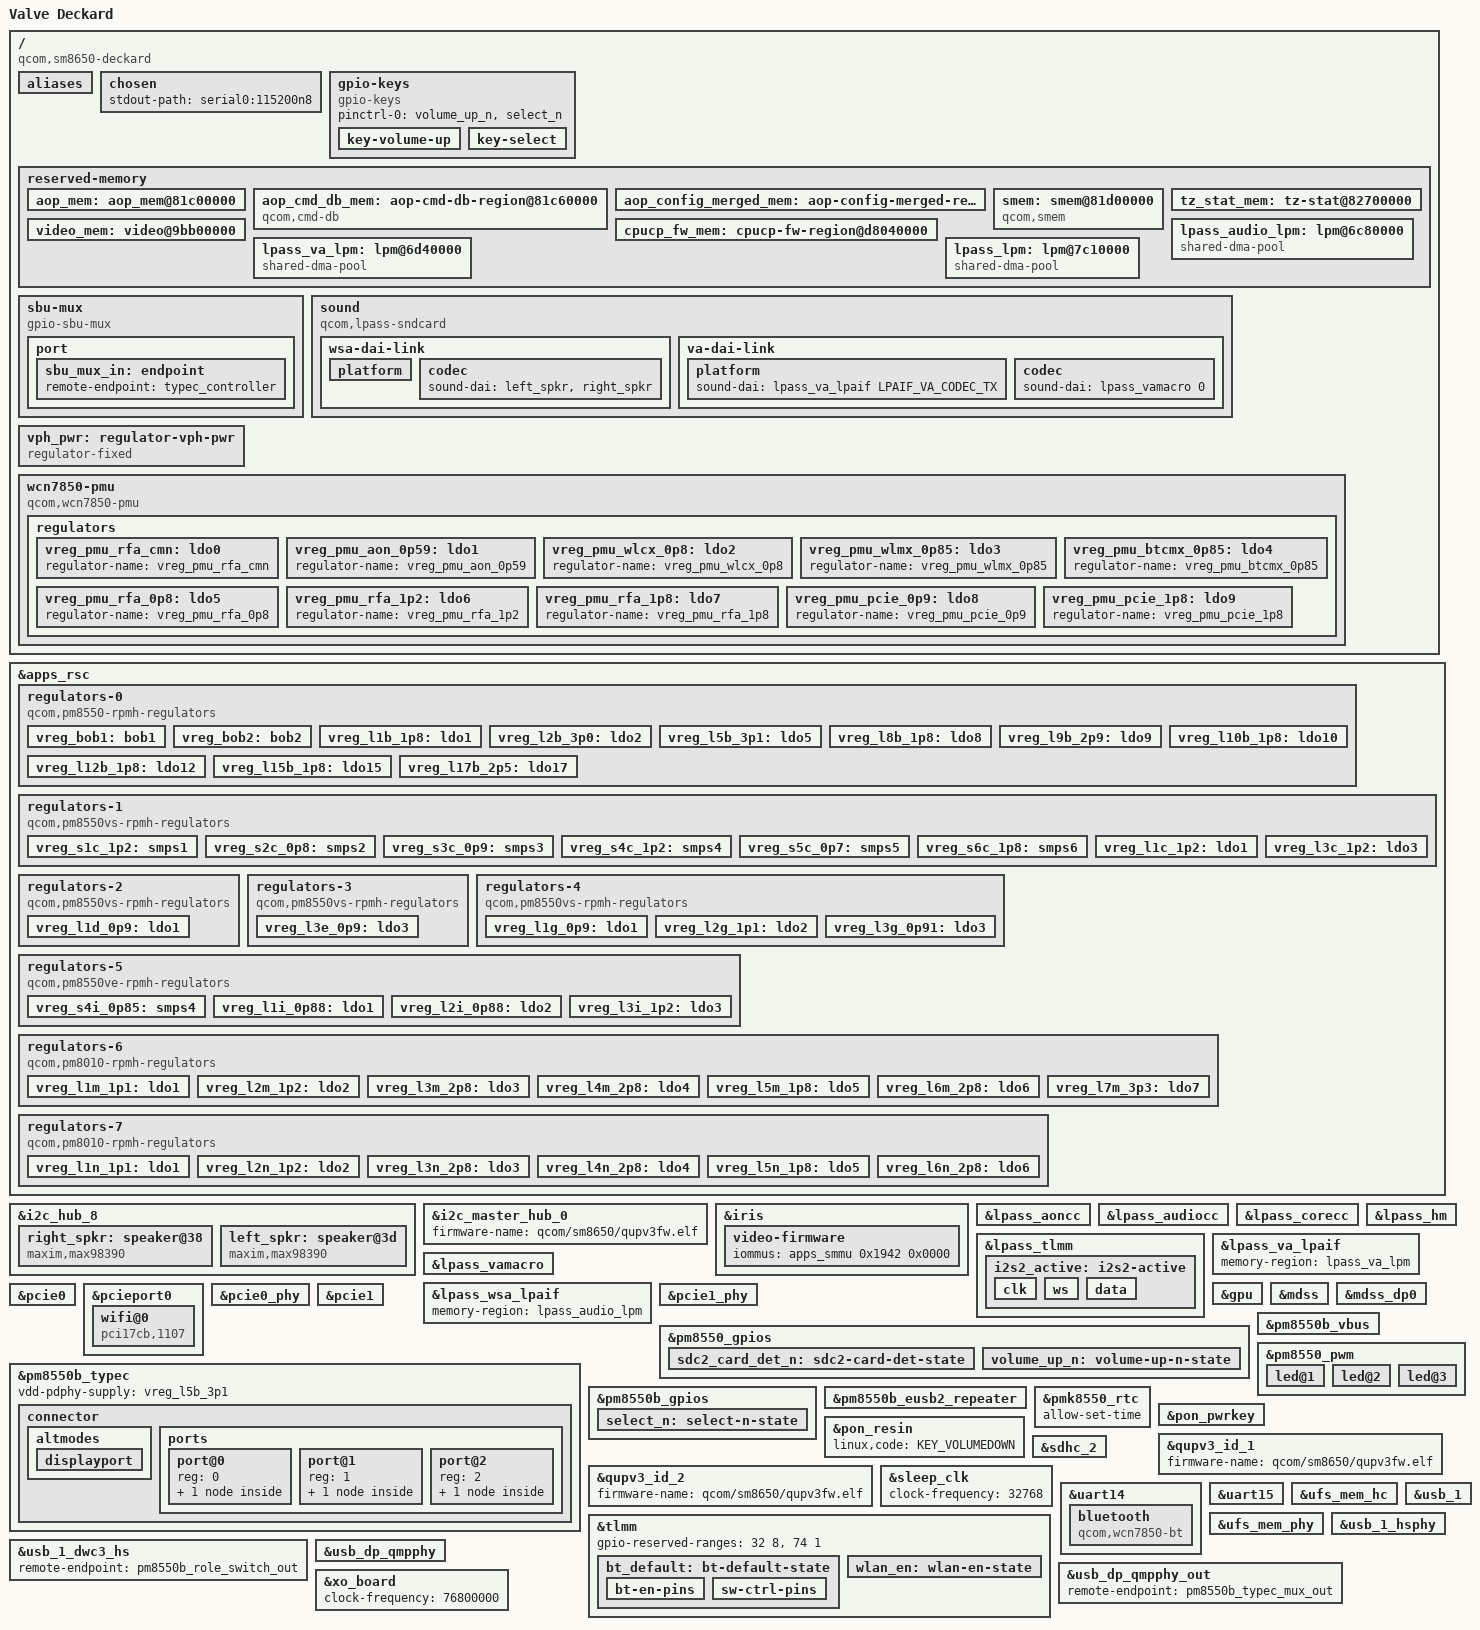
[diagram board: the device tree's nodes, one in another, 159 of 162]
// SPDX-License-Identifier: BSD-3-Clause
/*
 * Copyright (c) 2025
 */

/dts-v1/;

#include <dt-bindings/leds/common.h>
#include <dt-bindings/regulator/qcom,rpmh-regulator.h>
#include <dt-bindings/sound/qcom,lpaif-v5.h>
#include <dt-bindings/usb/pd.h>
#include "sm8650.dtsi"
#include "pm8010.dtsi"
#include "pm8550.dtsi"
#include "pm8550b.dtsi"
#define PMK8550VE_SID 8
#include "pm8550ve.dtsi"
#include "pm8550vs.dtsi"
#include "pmk8550.dtsi"

/* most of the sm8650.dtsi reserved-memory isn't applicable, redefine it from scratch
 * also delete anything that depends on the deleted regions to compile the dts
 */
/delete-node/ &reserved_memory;
/delete-node/ &remoteproc_mpss;
/delete-node/ &remoteproc_adsp;
/delete-node/ &remoteproc_cdsp;
/delete-node/ &ipa;
/delete-node/ &lpass_txmacro;
/delete-node/ &lpass_rxmacro;
/delete-node/ &lpass_wsamacro;
/delete-node/ &lpass_wsa2macro;
/delete-node/ &swr0;
/delete-node/ &swr1;
/delete-node/ &swr2;
/delete-node/ &swr3;

/ {
	model = "Valve Deckard";
	compatible = "qcom,sm8650-deckard", "qcom,sm8650";
	chassis-type = "embedded";

	/delete-node/ smp2p-adsp;
	/delete-node/ smp2p-cdsp;
	/delete-node/ smp2p-modem;

	aliases {
		serial0 = &uart15;
		serial1 = &uart14;
	};

	chosen {
		stdout-path = "serial0:115200n8";
	};

	gpio-keys {
		compatible = "gpio-keys";

		pinctrl-0 = <&volume_up_n>, <&select_n>;
		pinctrl-names = "default";

		key-volume-up {
			label = "Volume Up";
			linux,code = <KEY_VOLUMEUP>;
			gpios = <&pm8550_gpios 6 GPIO_ACTIVE_LOW>;
			debounce-interval = <15>;
			linux,can-disable;
		};

		key-select {
			label = "Select";
			linux,code = <KEY_SELECT>;
			gpios = <&pm8550b_gpios 5 GPIO_ACTIVE_LOW>;
			debounce-interval = <15>;
			linux,can-disable;
		};
	};

	reserved-memory {
		#address-cells = <2>;
		#size-cells = <2>;
		ranges;

		aop_mem: aop_mem@81c00000 {
			no-map;
			reg = <0x0 0x81c00000 0x0 0x60000>;
		};

		aop_cmd_db_mem: aop-cmd-db-region@81c60000 {
			compatible = "qcom,cmd-db";
			reg = <0x0 0x81c60000 0x0 0x20000>;
			no-map;
		};

		/* merged aop_config, tme_crash_dump, tme_log */
		aop_config_merged_mem: aop-config-merged-region@81c80000 {
			reg = <0x0 0x81c80000 0x0 0x75000>; // without TZ: size 0x64000
			no-map;
		};

		smem: smem@81d00000 {
			compatible = "qcom,smem";
			reg = <0x0 0x81d00000 0x0 0x200000>;
			hwlocks = <&tcsr_mutex 3>;
			no-map;
		};

		// with TZ only:
		tz_stat_mem: tz-stat@82700000 {
			reg = <0 0x82700000 0 0x100000>;
			no-map;
		};

		cpucp_fw_mem: cpucp-fw-region@d8040000 {
			reg = <0x0 0xd8040000 0x0 0x1b2000>;
			no-map;
		};

		/* note: can be any free 8MB region (driver needs a fixed region) */
		video_mem: video@9bb00000 {
			reg = <0 0x9bb00000 0 0x800000>;
			no-map;
		};

		/* not regular memory: */

		lpass_audio_lpm: lpm@6c80000 {
			compatible = "shared-dma-pool";
			reg = <0 0x06c80000 0 0x10000>;
			no-map;
		};

		lpass_va_lpm: lpm@6d40000 {
			compatible = "shared-dma-pool";
			reg = <0 0x06d40000 0 0x3000>;
			no-map;
		};

		lpass_lpm: lpm@7c10000 {
			compatible = "shared-dma-pool";
			reg = <0 0x07c10000 0 0x8000>;
			no-map;
		};
	};

	sbu-mux {
		compatible = "gpio-sbu-mux";

		enable-gpios = <&tlmm 86 GPIO_ACTIVE_LOW>;
		select-gpios = <&tlmm 82 GPIO_ACTIVE_HIGH>;

		mode-switch;
		orientation-switch;

		port {
			sbu_mux_in: endpoint {
				remote-endpoint = <&typec_controller>;
			};
		};

		// XXX: needs VREG_L05B_3P1, VREG_BOB2
	};

	sound {
		compatible = "qcom,lpass-sndcard";
		model = "SM8650-DECKARD";

		pinctrl-0 = <&i2s2_active>;
		pinctrl-names = "default";

		wsa-dai-link {
			link-name = "SPKR Playback";

			clocks = <&lpass_audiocc LPASS_AUDIO_CC_EXT_IF2_IBIT_CLK>;

			platform {
				sound-dai = <&lpass_wsa_lpaif LPAIF_WSA_LPASS_I2S2>;
			};

			codec {
				sound-dai = <&left_spkr>, <&right_spkr>;
			};
		};

		va-dai-link {
			link-name = "VA Capture";
			capture;

			platform {
				sound-dai = <&lpass_va_lpaif LPAIF_VA_CODEC_TX>;
			};

			codec {
				sound-dai = <&lpass_vamacro 0>;
			};
		};
	};

	vph_pwr: regulator-vph-pwr {
		compatible = "regulator-fixed";

		regulator-name = "vph_pwr";
		regulator-min-microvolt = <3700000>;
		regulator-max-microvolt = <3700000>;

		regulator-always-on;
		regulator-boot-on;
	};

	wcn7850-pmu {
		compatible = "qcom,wcn7850-pmu";

		pinctrl-names = "default";
		pinctrl-0 = <&wlan_en>, <&bt_default>;

		wlan-enable-gpios = <&tlmm 16 GPIO_ACTIVE_HIGH>;
		bt-enable-gpios = <&tlmm 17 GPIO_ACTIVE_HIGH>;

		vdd-supply = <&vreg_s4i_0p85>;
		vddio-supply = <&vreg_l15b_1p8>;
		vddio1p2-supply = <&vreg_l3c_1p2>;
		vddaon-supply = <&vreg_s2c_0p8>;
		vdddig-supply = <&vreg_s3c_0p9>;
		vddrfa1p2-supply = <&vreg_s1c_1p2>;
		vddrfa1p8-supply = <&vreg_s6c_1p8>;

		voltage-list = <944000 1800000 1200000 976000 916000 1316000 1864000>;

		clocks = <&rpmhcc RPMH_RF_CLK1>;

		regulators {
			vreg_pmu_rfa_cmn: ldo0 {
				regulator-name = "vreg_pmu_rfa_cmn";
			};

			vreg_pmu_aon_0p59: ldo1 {
				regulator-name = "vreg_pmu_aon_0p59";
			};

			vreg_pmu_wlcx_0p8: ldo2 {
				regulator-name = "vreg_pmu_wlcx_0p8";
			};

			vreg_pmu_wlmx_0p85: ldo3 {
				regulator-name = "vreg_pmu_wlmx_0p85";
			};

			vreg_pmu_btcmx_0p85: ldo4 {
				regulator-name = "vreg_pmu_btcmx_0p85";
			};

			vreg_pmu_rfa_0p8: ldo5 {
				regulator-name = "vreg_pmu_rfa_0p8";
			};

			vreg_pmu_rfa_1p2: ldo6 {
				regulator-name = "vreg_pmu_rfa_1p2";
			};

			vreg_pmu_rfa_1p8: ldo7 {
				regulator-name = "vreg_pmu_rfa_1p8";
			};

			vreg_pmu_pcie_0p9: ldo8 {
				regulator-name = "vreg_pmu_pcie_0p9";
			};

			vreg_pmu_pcie_1p8: ldo9 {
				regulator-name = "vreg_pmu_pcie_1p8";
			};
		};
	};
};

&apps_rsc {
	regulators-0 {
		compatible = "qcom,pm8550-rpmh-regulators";

		vdd-bob1-supply = <&vph_pwr>;
		vdd-bob2-supply = <&vph_pwr>;
		vdd-l1-l4-l10-supply = <&vreg_s6c_1p8>;
		vdd-l2-l13-l14-supply = <&vreg_bob1>;
		vdd-l3-supply = <&vreg_s1c_1p2>;
		vdd-l5-l16-supply = <&vreg_bob1>;
		vdd-l8-l9-supply = <&vreg_bob1>;
		vdd-l12-supply = <&vreg_s6c_1p8>;
		vdd-l15-supply = <&vreg_s6c_1p8>;
		vdd-l17-supply = <&vreg_bob2>;

		qcom,pmic-id = "b";

		vreg_bob1: bob1 {
			regulator-name = "vreg_bob1";
			regulator-min-microvolt = <3296000>; // note: min is 3008000, init is 3296000
			regulator-max-microvolt = <3960000>;
			regulator-initial-mode = <RPMH_REGULATOR_MODE_HPM>;
		};

		vreg_bob2: bob2 {
			regulator-name = "vreg_bob2";
			regulator-min-microvolt = <2720000>; // note: min is 2704000, init is 2720000
			regulator-max-microvolt = <3008000>;
			regulator-initial-mode = <RPMH_REGULATOR_MODE_HPM>;

			regulator-always-on; // XXX USB HS, SBU MUX
		};

		vreg_l1b_1p8: ldo1 {
			regulator-name = "vreg_l1b_1p8";
			regulator-min-microvolt = <1800000>;
			regulator-max-microvolt = <1800000>;
			regulator-initial-mode = <RPMH_REGULATOR_MODE_HPM>;

			regulator-always-on; // XXX sensors
		};

		vreg_l2b_3p0: ldo2 {
			regulator-name = "vreg_l2b_3p0";
			regulator-min-microvolt = <3008000>;
			regulator-max-microvolt = <3008000>;
			regulator-initial-mode = <RPMH_REGULATOR_MODE_HPM>;

			regulator-always-on; // XXX sensors
		};

		vreg_l5b_3p1: ldo5 {
			regulator-name = "vreg_l5b_3p1";
			regulator-min-microvolt = <3104000>;
			regulator-max-microvolt = <3104000>;
			regulator-initial-mode = <RPMH_REGULATOR_MODE_HPM>;
			regulator-allow-set-load;
			regulator-allowed-modes = <RPMH_REGULATOR_MODE_LPM
						   RPMH_REGULATOR_MODE_HPM>;
			regulator-always-on; // XXX SBU MUX
		};

		vreg_l8b_1p8: ldo8 {
			regulator-name = "vreg_l8b_1p8";
			regulator-min-microvolt = <1800000>;
			regulator-max-microvolt = <1800000>;
			regulator-initial-mode = <RPMH_REGULATOR_MODE_HPM>;
			regulator-allow-set-load;
			regulator-allowed-modes = <RPMH_REGULATOR_MODE_LPM
						   RPMH_REGULATOR_MODE_HPM>;
		};

		vreg_l9b_2p9: ldo9 {
			regulator-name = "vreg_l9b_2p9";
			regulator-min-microvolt = <2960000>;
			regulator-max-microvolt = <2960000>;
			regulator-initial-mode = <RPMH_REGULATOR_MODE_HPM>;
			regulator-allow-set-load;
			regulator-allowed-modes = <RPMH_REGULATOR_MODE_LPM
						   RPMH_REGULATOR_MODE_HPM>;
		};

		vreg_l10b_1p8: ldo10 {
			regulator-name = "vreg_l10b_1p8";
			regulator-min-microvolt = <1800000>;
			regulator-max-microvolt = <1800000>;
			regulator-initial-mode = <RPMH_REGULATOR_MODE_HPM>;

			regulator-always-on; // XXX DMIC
		};

		vreg_l12b_1p8: ldo12 {
			regulator-name = "vreg_l12b_1p8";
			regulator-min-microvolt = <1800000>;
			regulator-max-microvolt = <1800000>;
			regulator-initial-mode = <RPMH_REGULATOR_MODE_HPM>;
			regulator-allow-set-load;
			regulator-allowed-modes = <RPMH_REGULATOR_MODE_LPM
						   RPMH_REGULATOR_MODE_HPM>;
		};

		vreg_l15b_1p8: ldo15 {
			regulator-name = "vreg_l15b_1p8";
			regulator-min-microvolt = <1800000>;
			regulator-max-microvolt = <1800000>;
			regulator-initial-mode = <RPMH_REGULATOR_MODE_HPM>;
			regulator-allow-set-load;
			regulator-allowed-modes = <RPMH_REGULATOR_MODE_LPM
						   RPMH_REGULATOR_MODE_HPM>;
			regulator-always-on; // XXX: 1.8V pull ups
		};

		vreg_l17b_2p5: ldo17 {
			regulator-name = "vreg_l17b_2p5";
			regulator-min-microvolt = <2504000>;
			regulator-max-microvolt = <2504000>;
			regulator-initial-mode = <RPMH_REGULATOR_MODE_HPM>;
			regulator-allow-set-load;
			regulator-allowed-modes = <RPMH_REGULATOR_MODE_LPM
						   RPMH_REGULATOR_MODE_HPM>;
		};
	};

	regulators-1 {
		compatible = "qcom,pm8550vs-rpmh-regulators";

		vdd-l1-supply = <&vreg_s1c_1p2>;
		vdd-l3-supply = <&vreg_s1c_1p2>;
		vdd-s1-supply = <&vph_pwr>;
		vdd-s2-supply = <&vph_pwr>;
		vdd-s3-supply = <&vph_pwr>;
		vdd-s4-supply = <&vph_pwr>;
		vdd-s5-supply = <&vph_pwr>;
		vdd-s6-supply = <&vph_pwr>;

		qcom,pmic-id = "c";

		vreg_s1c_1p2: smps1 {
			regulator-name = "vreg_s1c_1p2";
			regulator-min-microvolt = <1224000>;
			regulator-max-microvolt = <1348000>;
			// init 1256000
			regulator-initial-mode = <RPMH_REGULATOR_MODE_HPM>;

			regulator-always-on; // USB, UFS?
		};

		vreg_s2c_0p8: smps2 {
			regulator-name = "vreg_s2c_0p8";
			regulator-min-microvolt = <500000>;
			regulator-max-microvolt = <1036000>;
			// init 852000
			regulator-initial-mode = <RPMH_REGULATOR_MODE_HPM>;
		};

		vreg_s3c_0p9: smps3 {
			regulator-name = "vreg_s3c_0p9";
			regulator-min-microvolt = <904000>;
			regulator-max-microvolt = <1064000>;
			// init 976000
			regulator-initial-mode = <RPMH_REGULATOR_MODE_HPM>;
		};

		vreg_s4c_1p2: smps4 {
			regulator-name = "vreg_s4c_1p2";
			regulator-min-microvolt = <1200000>;
			regulator-max-microvolt = <1280000>;
			// init 1224000
			regulator-initial-mode = <RPMH_REGULATOR_MODE_HPM>;
		};

		vreg_s5c_0p7: smps5 {
			regulator-name = "vreg_s5c_0p7";
			regulator-min-microvolt = <300000>;
			regulator-max-microvolt = <900000>;
			// init 752000
			regulator-initial-mode = <RPMH_REGULATOR_MODE_HPM>;
		};

		vreg_s6c_1p8: smps6 {
			regulator-name = "vreg_s6c_1p8";
			regulator-min-microvolt = <1856000>;
			regulator-max-microvolt = <2000000>;
			// init 1856000
			regulator-initial-mode = <RPMH_REGULATOR_MODE_HPM>;
		};

		vreg_l1c_1p2: ldo1 {
			regulator-name = "vreg_l1c_1p2";
			regulator-min-microvolt = <1200000>; // note: min 1100000
			regulator-max-microvolt = <1200000>;
			regulator-initial-mode = <RPMH_REGULATOR_MODE_HPM>;
		};

		vreg_l3c_1p2: ldo3 {
			regulator-name = "vreg_l3c_1p2";
			regulator-min-microvolt = <1200000>;
			regulator-max-microvolt = <1200000>;
			regulator-initial-mode = <RPMH_REGULATOR_MODE_HPM>;
			regulator-allow-set-load;
			regulator-allowed-modes = <RPMH_REGULATOR_MODE_LPM
						   RPMH_REGULATOR_MODE_HPM>;
			regulator-always-on; // XXX: 1.2V pull ups
		};
	};

	regulators-2 {
		compatible = "qcom,pm8550vs-rpmh-regulators";
		qcom,pmic-id = "d";

		vdd-l1-supply = <&vreg_s3c_0p9>;

		vreg_l1d_0p9: ldo1 {
			regulator-name = "vreg_l1d_0p9";
			regulator-min-microvolt = <912000>; // note: min 880000
			regulator-max-microvolt = <920000>;
			regulator-initial-mode = <RPMH_REGULATOR_MODE_HPM>;
			regulator-allow-set-load;
			regulator-allowed-modes = <RPMH_REGULATOR_MODE_LPM
						   RPMH_REGULATOR_MODE_HPM>;
		};
	};

	regulators-3 {
		compatible = "qcom,pm8550vs-rpmh-regulators";

		vdd-l3-supply = <&vreg_s3c_0p9>;

		qcom,pmic-id = "e";

		vreg_l3e_0p9: ldo3 {
			regulator-name = "vreg_l3e_0p9";
			regulator-min-microvolt = <880000>;
			regulator-max-microvolt = <920000>;
			regulator-initial-mode = <RPMH_REGULATOR_MODE_HPM>;
			regulator-allow-set-load;
			regulator-allowed-modes = <RPMH_REGULATOR_MODE_LPM
						   RPMH_REGULATOR_MODE_HPM>;
		};
	};

	regulators-4 {
		compatible = "qcom,pm8550vs-rpmh-regulators";

		vdd-l1-supply = <&vreg_s3c_0p9>;
		vdd-l2-supply = <&vreg_s1c_1p2>;
		vdd-l3-supply = <&vreg_s3c_0p9>;

		qcom,pmic-id = "g";

		vreg_l1g_0p9: ldo1 {
			regulator-name = "vreg_l1g_0p9";
			regulator-min-microvolt = <912000>;
			regulator-max-microvolt = <920000>;
			regulator-initial-mode = <RPMH_REGULATOR_MODE_HPM>;
			// QLINK ?
		};

		vreg_l2g_1p1: ldo2 {
			regulator-name = "vreg_l2g_1p1";
			regulator-min-microvolt = <1104000>;
			regulator-max-microvolt = <1104000>;
			regulator-initial-mode = <RPMH_REGULATOR_MODE_HPM>;
		};

		vreg_l3g_0p91: ldo3 {
			regulator-name = "vreg_l3g_0p91";
			regulator-min-microvolt = <880000>;
			regulator-max-microvolt = <912000>;
			regulator-initial-mode = <RPMH_REGULATOR_MODE_HPM>;
		};
	};

	regulators-5 {
		compatible = "qcom,pm8550ve-rpmh-regulators";

		vdd-l1-supply = <&vreg_s3c_0p9>;
		vdd-l2-supply = <&vreg_s3c_0p9>;
		vdd-l3-supply = <&vreg_s1c_1p2>;
		vdd-s4-supply = <&vph_pwr>;

		qcom,pmic-id = "i";

		vreg_s4i_0p85: smps4 {
			regulator-name = "vreg_s4i_0p85";
			regulator-min-microvolt = <852000>;
			regulator-max-microvolt = <1004000>;
			// init 852000
			regulator-initial-mode = <RPMH_REGULATOR_MODE_HPM>;
		};

		vreg_l1i_0p88: ldo1 {
			regulator-name = "vreg_l1i_0p88";
			regulator-min-microvolt = <880000>;
			regulator-max-microvolt = <912000>;
			regulator-initial-mode = <RPMH_REGULATOR_MODE_HPM>;
			regulator-allow-set-load;
			regulator-allowed-modes = <RPMH_REGULATOR_MODE_LPM
						   RPMH_REGULATOR_MODE_HPM>;
		};

		vreg_l2i_0p88: ldo2 {
			regulator-name = "vreg_l2i_0p88";
			regulator-min-microvolt = <880000>;
			regulator-max-microvolt = <912000>;
			regulator-initial-mode = <RPMH_REGULATOR_MODE_HPM>;
			regulator-allow-set-load;
			regulator-allowed-modes = <RPMH_REGULATOR_MODE_LPM
						   RPMH_REGULATOR_MODE_HPM>;

			//regulator-always-on; // CSI PHY
		};

		vreg_l3i_1p2: ldo3 {
			regulator-name = "vreg_l3i_1p2";
			regulator-min-microvolt = <1200000>;
			regulator-max-microvolt = <1200000>;
			regulator-initial-mode = <RPMH_REGULATOR_MODE_HPM>;
			regulator-allow-set-load;
			regulator-allowed-modes = <RPMH_REGULATOR_MODE_LPM
						   RPMH_REGULATOR_MODE_HPM>;

			//regulator-always-on; // CSI PHY
		};
	};

	regulators-6 {
		compatible = "qcom,pm8010-rpmh-regulators";
		qcom,pmic-id = "m";

		vdd-l1-l2-supply = <&vreg_s1c_1p2>;
		vdd-l3-l4-supply = <&vreg_bob2>;
		vdd-l5-supply = <&vreg_s6c_1p8>;
		vdd-l6-supply = <&vreg_bob1>;
		vdd-l7-supply = <&vreg_bob1>;

		vreg_l1m_1p1: ldo1 {
			regulator-name = "vreg_l1m_1p1";
			regulator-min-microvolt = <1104000>;
			regulator-max-microvolt = <1104000>;
			regulator-initial-mode = <RPMH_REGULATOR_MODE_HPM>;
			regulator-allow-set-load;
			regulator-allowed-modes = <RPMH_REGULATOR_MODE_LPM
						   RPMH_REGULATOR_MODE_HPM>;
		};

		vreg_l2m_1p2: ldo2 {
			regulator-name = "vreg_l2m_1p2";
			regulator-min-microvolt = <1200000>;
			regulator-max-microvolt = <1200000>;
			regulator-initial-mode = <RPMH_REGULATOR_MODE_HPM>;
			regulator-allow-set-load;
			regulator-allowed-modes = <RPMH_REGULATOR_MODE_LPM
						   RPMH_REGULATOR_MODE_HPM>;
		};

		vreg_l3m_2p8: ldo3 {
			regulator-name = "vreg_l3m_2p8";
			regulator-min-microvolt = <2800000>;
			regulator-max-microvolt = <2800000>;
			regulator-initial-mode = <RPMH_REGULATOR_MODE_HPM>;
		};

		vreg_l4m_2p8: ldo4 {
			regulator-name = "vreg_l4m_2p8";
			regulator-min-microvolt = <2800000>;
			regulator-max-microvolt = <2800000>;
			regulator-initial-mode = <RPMH_REGULATOR_MODE_HPM>;
		};

		vreg_l5m_1p8: ldo5 {
			regulator-name = "vreg_l5m_1p8";
			regulator-min-microvolt = <1800000>;
			regulator-max-microvolt = <1800000>;
			regulator-initial-mode = <RPMH_REGULATOR_MODE_HPM>;
		};

		vreg_l6m_2p8: ldo6 {
			regulator-name = "vreg_l6m_2p8";
			regulator-min-microvolt = <2800000>;
			regulator-max-microvolt = <2800000>;
			regulator-initial-mode = <RPMH_REGULATOR_MODE_HPM>;
		};

		vreg_l7m_3p3: ldo7 {
			regulator-name = "vreg_l7m_3p3";
			regulator-min-microvolt = <3304000>;
			regulator-max-microvolt = <3304000>;
			regulator-initial-mode = <RPMH_REGULATOR_MODE_HPM>;

			regulator-always-on;
		};
	};

	regulators-7 {
		compatible = "qcom,pm8010-rpmh-regulators";
		qcom,pmic-id = "n";

		vdd-l1-l2-supply = <&vreg_s1c_1p2>;
		vdd-l3-l4-supply = <&vreg_bob2>;
		vdd-l5-supply = <&vreg_s6c_1p8>;
		vdd-l6-supply = <&vreg_bob1>;

		vreg_l1n_1p1: ldo1 {
			regulator-name = "vreg_l1n_1p1";
			regulator-min-microvolt = <1104000>;
			regulator-max-microvolt = <1104000>;
			regulator-initial-mode = <RPMH_REGULATOR_MODE_HPM>;
			regulator-allow-set-load;
			regulator-allowed-modes = <RPMH_REGULATOR_MODE_LPM
						   RPMH_REGULATOR_MODE_HPM>;
		};

		vreg_l2n_1p2: ldo2 {
			regulator-name = "vreg_l2n_1p2";
			regulator-min-microvolt = <1200000>;
			regulator-max-microvolt = <1200000>;
			regulator-initial-mode = <RPMH_REGULATOR_MODE_HPM>;
			regulator-allow-set-load;
			regulator-allowed-modes = <RPMH_REGULATOR_MODE_LPM
						   RPMH_REGULATOR_MODE_HPM>;
		};

		vreg_l3n_2p8: ldo3 {
			regulator-name = "vreg_l3n_2p8";
			regulator-min-microvolt = <2800000>;
			regulator-max-microvolt = <2800000>;
			regulator-initial-mode = <RPMH_REGULATOR_MODE_HPM>;
		};

		vreg_l4n_2p8: ldo4 {
			regulator-name = "vreg_l4n_2p8";
			regulator-min-microvolt = <2800000>;
			regulator-max-microvolt = <2800000>;
			regulator-initial-mode = <RPMH_REGULATOR_MODE_HPM>;
		};

		vreg_l5n_1p8: ldo5 {
			regulator-name = "vreg_l5n_1p8";
			regulator-min-microvolt = <1800000>;
			regulator-max-microvolt = <1800000>;
			regulator-initial-mode = <RPMH_REGULATOR_MODE_HPM>;
		};

		vreg_l6n_2p8: ldo6 {
			regulator-name = "vreg_l6n_2p8";
			regulator-min-microvolt = <2800000>;
			regulator-max-microvolt = <2800000>;
			regulator-initial-mode = <RPMH_REGULATOR_MODE_HPM>;
		};
	};
};

#if 0
&i2c2 {
	status = "okay";

	eeprom@50 {
		compatible  = "atmel,24c32";
		label		= "strap_eeprom";
		reg         = <0x50>;
		//wp-gpios = <&tlmm 78 GPIO_ACTIVE_HIGH>;
		vcc-supply  = <&vreg_l15b_1p8>;
	};
};

&i2c5 {
	status = "okay";

	eeprom@50 {
		compatible  = "atmel,24c32";
		status      = "okay";
		label		= "core_eeprom";
		reg         = <0x50>;
		wp-gpios = <&tlmm 78 GPIO_ACTIVE_HIGH>;
		vcc-supply  = <&vreg_l15b_1p8>;
	};
};
#endif

&i2c_hub_8 {
	status = "okay";

	right_spkr: speaker@38 {
		compatible = "maxim,max98390";
		reg = <0x38>;
		maxim,temperature_calib = <1024>; // TODO
		maxim,r0_calib = <100232>; // TODO
		reset-gpios = <&tlmm 73 GPIO_ACTIVE_LOW>;
		// irq-gpios = <&tlmm 186 GPIO_ACTIVE_LOW>;  XXX TODO add IRQ support to driver, set as open drain
		#sound-dai-cells = <0>;
		sound-name-prefix = "Speaker Right";
	};

	left_spkr: speaker@3d {
		compatible = "maxim,max98390";
		reg = <0x3d>;
		maxim,temperature_calib = <1024>; // TODO
		maxim,r0_calib = <100232>; // TODO
		reset-gpios = <&tlmm 161 GPIO_ACTIVE_LOW>;
		// irq-gpios = <&tlmm 77 GPIO_ACTIVE_LOW>;  XXX TODO add IRQ support to driver, set as open drain
		#sound-dai-cells = <0>;
		sound-name-prefix = "Speaker Left";
	};
};

&i2c_master_hub_0 {
	status = "okay";
	firmware-name = "qcom/sm8650/qupv3fw.elf";
};

&iris {
	status = "okay";

	video-firmware {
		iommus = <&apps_smmu 0x1942 0x0000>;
	};
};

&lpass_aoncc {
	status = "okay";
};

&lpass_audiocc {
	status = "okay";
};

&lpass_corecc {
	status = "okay";
};

&lpass_hm {
	status = "okay";
};

&lpass_tlmm {
	status = "okay";
	/delete-property/ clocks;
	/delete-property/ clocks-names;

	i2s2_active: i2s2-active {
		clk {
			pins = "gpio10";
			function = "i2s2_clk";
			drive-strength = <8>;
			bias-disable;
			output-high;
		};

		ws {
			pins = "gpio11";
			function = "i2s2_ws";
			drive-strength = <8>;
			output-high;
		};

		data {
			pins = "gpio15", "gpio16";
			function = "i2s2_data";
			drive-strength = <8>;
			bias-disable;
			output-high;
		};
	};
};

&lpass_va_lpaif {
	status = "okay";
	memory-region = <&lpass_va_lpm>;
};

&lpass_vamacro {
	clocks = <&lpass_aoncc LPASS_AON_CC_TX_MCLK_CLK>;
	clock-names = "mclk";
	pinctrl-0 = <&dmic01_default>;
	pinctrl-names = "default";
	vdd-micb-supply = <&vreg_l10b_1p8>;
	qcom,dmic-sample-rate = <2400000>; /* or 3200000 */
};

&lpass_wsa_lpaif {
	status = "okay";
	memory-region = <&lpass_audio_lpm>;
};

&gpu {
	status = "okay";

	/delete-node/ zap-shader;
};

&mdss {
	status = "okay";
};

&mdss_dp0 {
	status = "okay";
};

&pcie0 {
	wake-gpios = <&tlmm 96 GPIO_ACTIVE_HIGH>;
	perst-gpios = <&tlmm 94 GPIO_ACTIVE_LOW>;

	pinctrl-0 = <&pcie0_default_state>;
	pinctrl-names = "default";

	status = "okay";
};

&pcieport0 {
	wifi@0 {
		compatible = "pci17cb,1107";
		reg = <0x10000 0x0 0x0 0x0 0x0>;

		vddrfacmn-supply = <&vreg_pmu_rfa_cmn>;
		vddaon-supply = <&vreg_pmu_aon_0p59>;
		vddwlcx-supply = <&vreg_pmu_wlcx_0p8>;
		vddwlmx-supply = <&vreg_pmu_wlmx_0p85>;
		vddrfa0p8-supply = <&vreg_pmu_rfa_0p8>;
		vddrfa1p2-supply = <&vreg_pmu_rfa_1p2>;
		vddrfa1p8-supply = <&vreg_pmu_rfa_1p8>;
		vddpcie0p9-supply = <&vreg_pmu_pcie_0p9>;
		vddpcie1p8-supply = <&vreg_pmu_pcie_1p8>;
	};
};

&pcie0_phy {
	vdda-phy-supply = <&vreg_l1i_0p88>;
	vdda-pll-supply = <&vreg_l3i_1p2>;

	status = "okay";
};

&pcie1 {
	wake-gpios = <&tlmm 99 GPIO_ACTIVE_HIGH>;
	perst-gpios = <&tlmm 97 GPIO_ACTIVE_LOW>;

	pinctrl-0 = <&pcie1_default_state>;
	pinctrl-names = "default";

	status = "okay";
};

&pcie1_phy {
	vdda-phy-supply = <&vreg_l3e_0p9>;
	vdda-pll-supply = <&vreg_l3i_1p2>;
	vdda-qref-supply = <&vreg_l1i_0p88>;

	status = "okay";
};

&pm8550_gpios {
	sdc2_card_det_n: sdc2-card-det-state {
		pins = "gpio12";
		function = "normal";
		bias-pull-up;
		input-enable;
		output-disable;
		power-source = <1>; /* 1.8 V */
	};

	volume_up_n: volume-up-n-state {
		pins = "gpio6";
		function = "normal";
		bias-pull-up;
		input-enable;
		power-source = <1>;
	};
};

&pm8550b_typec {
	status = "okay";

	vdd-pdphy-supply = <&vreg_l5b_3p1>;

	connector {
		power-role = "dual";
		data-role = "dual";
		try-power-role = "sink";
		source-pdos = <PDO_FIXED(5000, 3000, PDO_FIXED_DUAL_ROLE | PDO_FIXED_DATA_SWAP | PDO_FIXED_USB_COMM)>;

		//sink-pdos needs to have 5000mV entry first otherwise will not probe
		sink-pdos = <PDO_FIXED(5000, 3000, PDO_FIXED_DUAL_ROLE | PDO_FIXED_DATA_SWAP | PDO_FIXED_USB_COMM)>,
                    <PDO_FIXED(9000, 3000, PDO_FIXED_DUAL_ROLE | PDO_FIXED_DATA_SWAP | PDO_FIXED_USB_COMM)>,
                    <PDO_FIXED(12000, 3000, PDO_FIXED_DUAL_ROLE | PDO_FIXED_DATA_SWAP | PDO_FIXED_USB_COMM)>,
                    <PDO_FIXED(15000, 3000, PDO_FIXED_DUAL_ROLE | PDO_FIXED_DATA_SWAP | PDO_FIXED_USB_COMM)>;
		op-sink-microwatt = <15000000>;

		altmodes {
			displayport {
				svid = /bits/ 16 <0xff01>;
				vdo = <0x00001c46>;
			};
		};

		ports {
			#address-cells = <1>;
			#size-cells = <0>;

			port@0 {
				reg = <0>;

				pm8550b_role_switch_out: endpoint {
					remote-endpoint = <&usb_1_dwc3_hs>;
				};
			};

			port@1 {
				reg = <1>;

				typec_controller: endpoint {
					remote-endpoint = <&sbu_mux_in>;
				};
			};

			port@2 {
				reg = <2>;

				pm8550b_typec_mux_out: endpoint {
					remote-endpoint = <&usb_dp_qmpphy_out>;
				};
			};
		};
	};

};

&pm8550b_vbus {
	status = "okay";
};

&pm8550_pwm {
	#address-cells = <1>;
	#size-cells = <0>;

	status = "okay";

	led@1 {
		reg = <1>;
		function = LED_FUNCTION_STATUS;
		color = <LED_COLOR_ID_RED>;
		default-state = "off";
	};

	led@2 {
		reg = <2>;
		function = LED_FUNCTION_STATUS;
		color = <LED_COLOR_ID_GREEN>;
		default-state = "off";
	};

	led@3 {
		reg = <3>;
		function = LED_FUNCTION_STATUS;
		color = <LED_COLOR_ID_BLUE>;
		default-state = "off";
	};
};

&pm8550b_gpios {
	select_n: select-n-state {
		pins = "gpio5";
		function = "normal";
		bias-pull-up;
		input-enable;
		power-source = <1>;
	};
};

&pm8550b_eusb2_repeater {
	vdd18-supply = <&vreg_l15b_1p8>;
	vdd3-supply = <&vreg_l5b_3p1>;
};

&pmk8550_rtc {
	allow-set-time;
};

&pon_pwrkey {
	status = "okay";
};

&pon_resin {
	linux,code = <KEY_VOLUMEDOWN>;

	status = "okay";
};

&qupv3_id_1 {
	status = "okay";

	firmware-name = "qcom/sm8650/qupv3fw.elf";
};

&qupv3_id_2 {
	status = "okay";

	firmware-name = "qcom/sm8650/qupv3fw.elf";
};

&sdhc_2 {
	cd-gpios = <&pm8550_gpios 12 GPIO_ACTIVE_HIGH>;

	vmmc-supply = <&vreg_l9b_2p9>;
	vqmmc-supply = <&vreg_l8b_1p8>;
	bus-width = <4>;
	no-sdio;
	no-mmc;

	pinctrl-0 = <&sdc2_default>, <&sdc2_card_det_n>;
	pinctrl-1 = <&sdc2_sleep>, <&sdc2_card_det_n>;
	pinctrl-names = "default", "sleep";

	status = "okay";
};

&sleep_clk {
	clock-frequency = <32768>;
};

&tlmm {
	/* Reserved I/Os for NFC */
	gpio-reserved-ranges = <32 8>, <74 1>;

	bt_default: bt-default-state {
		bt-en-pins {
			pins = "gpio17";
			function = "gpio";
			drive-strength = <16>;
			bias-disable;
		};

		sw-ctrl-pins {
			pins = "gpio18";
			function = "gpio";
			bias-pull-down;
		};
	};

	wlan_en: wlan-en-state {
		pins = "gpio16";
		function = "gpio";
		drive-strength = <8>;
		bias-pull-down;
	};
};

&uart14 {
	status = "okay";

	bluetooth {
		compatible = "qcom,wcn7850-bt";

		vddrfacmn-supply = <&vreg_pmu_rfa_cmn>;
		vddaon-supply = <&vreg_pmu_aon_0p59>;
		vddwlcx-supply = <&vreg_pmu_wlcx_0p8>;
		vddwlmx-supply = <&vreg_pmu_wlmx_0p85>;
		vddrfa0p8-supply = <&vreg_pmu_rfa_0p8>;
		vddrfa1p2-supply = <&vreg_pmu_rfa_1p2>;
		vddrfa1p8-supply = <&vreg_pmu_rfa_1p8>;

		max-speed = <3200000>;
	};
};

&uart15 {
	status = "okay";
};

&ufs_mem_hc {
	reset-gpios = <&tlmm 210 GPIO_ACTIVE_LOW>;

	vcc-supply = <&vreg_l17b_2p5>;
	vcc-max-microamp = <1300000>;
	vccq-supply = <&vreg_l1c_1p2>;
	vccq-max-microamp = <1200000>;

	status = "okay";
};

&ufs_mem_phy {
	vdda-phy-supply = <&vreg_l1d_0p9>;
	vdda-pll-supply = <&vreg_l3i_1p2>;

	status = "okay";
};

&usb_1 {
	dr_mode = "otg";
	usb-role-switch;

	status = "okay";
};

&usb_1_dwc3_hs {
	remote-endpoint = <&pm8550b_role_switch_out>;
};

&usb_1_hsphy {
	vdd-supply = <&vreg_l1i_0p88>;
	vdda12-supply = <&vreg_l3i_1p2>;

	phys = <&pm8550b_eusb2_repeater>;

	status = "okay";
};

&usb_dp_qmpphy {
	vdda-phy-supply = <&vreg_l3i_1p2>;
	vdda-pll-supply = <&vreg_l3g_0p91>;

	status = "okay";
};

&usb_dp_qmpphy_out {
	remote-endpoint = <&pm8550b_typec_mux_out>;
};

&xo_board {
	clock-frequency = <76800000>;
};
